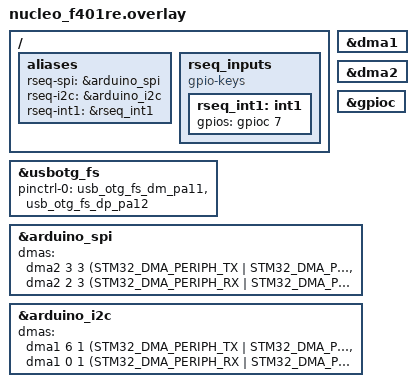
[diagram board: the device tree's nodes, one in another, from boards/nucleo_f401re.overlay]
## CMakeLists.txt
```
# SPDX-License-Identifier: Apache-2.0
#
# rseq MCU firmware (C + Rust). rust_cargo_application() builds the rustapp
# staticlib and provides main()→rust_main(); the C files are the FFI shims.

cmake_minimum_required(VERSION 3.20.0)

find_package(Zephyr REQUIRED HINTS $ENV{ZEPHYR_BASE})

project(rseq_f429zi)

rust_cargo_application()

target_sources(app PRIVATE
  src/zephyr_cdc_ffi.c
  src/zephyr_bus_ffi.c
)
```

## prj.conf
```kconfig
# SPDX-License-Identifier: Apache-2.0
#
# rseq MCU firmware (Nucleo boards): rseq-link over USB CDC + physical buses.

# ---- Rust (zephyr crate supplies global allocator + panic handler + log) ----
CONFIG_RUST=y
CONFIG_RUST_ALLOC=y

# ---- Console / logs on USART3 (ST-Link VCP) ----
CONFIG_CONSOLE=y
CONFIG_UART_CONSOLE=y
CONFIG_PRINTK=y
CONFIG_LOG=y
CONFIG_LOG_BACKEND_UART=y
CONFIG_LOG_BACKEND_RTT=n
CONFIG_USE_SEGGER_RTT=n
CONFIG_SERIAL=y
CONFIG_UART_INTERRUPT_DRIVEN=y

# ---- New USB CDC device stack (1 CDC port = rseq-link transport) ----
CONFIG_USB_DEVICE_STACK_NEXT=y
CONFIG_USBD_CDC_ACM_CLASS=y
CONFIG_CDC_ACM_SERIAL_INITIALIZE_AT_BOOT=n
CONFIG_UART_LINE_CTRL=y
CONFIG_HWINFO=y

# ---- Physical buses exposed to the rseq VM ----
CONFIG_SPI=y
CONFIG_I2C=y
CONFIG_GPIO=y

# ---- Stack: rseq-vm raw buffer + scratch + TracingBus frame during EXEC/IRQ ----
CONFIG_MAIN_STACK_SIZE=24576

# Avoid UART conflicts; console stays on USART3, protocol on USB CDC.
CONFIG_SHELL=n
```

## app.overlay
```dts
/*
 * Copyright (c) 2026 rseq contributors
 * SPDX-License-Identifier: Apache-2.0
 *
 * rseq MCU common overlay.
 *
 * Board-specific wiring lives in boards/<board>.overlay. Chip bus/address
 * selection is supplied by the rseq script, so this file stays transport-only.
 */

/* USB CDC-ACM — the rseq-link transport channel. */
&zephyr_udc0 {
	cdc_acm_uart0: cdc_acm_uart0 {
		compatible = "zephyr,cdc-acm-uart";
	};
};
```

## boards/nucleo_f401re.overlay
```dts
/*
 * Copyright (c) 2026 rseq contributors
 * SPDX-License-Identifier: Apache-2.0
 *
 * Nucleo F401RE board wiring for the rseq generic bus bridge firmware.
 *
 * Note: the application still needs a zephyr_udc0 USB device node for the CDC
 * transport. This board overlay exposes the Arduino bus/INT wiring;
 * USB availability is determined by the upstream board/SoC devicetree.
 */

#include <zephyr/dt-bindings/gpio/gpio.h>

zephyr_udc0: &usbotg_fs {
	pinctrl-0 = <&usb_otg_fs_dm_pa11 &usb_otg_fs_dp_pa12>;
	pinctrl-names = "default";
	status = "okay";
};

#include "../app.overlay"

/ {
	aliases {
		rseq-spi = &arduino_spi;
		rseq-i2c = &arduino_i2c;
		rseq-int1 = &rseq_int1;
	};

	rseq_inputs {
		compatible = "gpio-keys";

		/* Arduino D9 on Nucleo F401RE. */
		rseq_int1: int1 {
			gpios = <&gpioc 7 GPIO_ACTIVE_HIGH>;
		};
	};
};

&dma1 {
	status = "okay";
};

&dma2 {
	status = "okay";
};

&gpioc {
	status = "okay";
};

&arduino_spi {
	dmas = <&dma2 3 3 (STM32_DMA_PERIPH_TX | STM32_DMA_PRIORITY_HIGH)
		STM32_DMA_FIFO_FULL>,
	       <&dma2 2 3 (STM32_DMA_PERIPH_RX | STM32_DMA_PRIORITY_HIGH)
		STM32_DMA_FIFO_FULL>;
	dma-names = "tx", "rx";
};

&arduino_i2c {
	dmas = <&dma1 6 1 (STM32_DMA_PERIPH_TX | STM32_DMA_PRIORITY_HIGH)
		STM32_DMA_FIFO_FULL>,
	       <&dma1 0 1 (STM32_DMA_PERIPH_RX | STM32_DMA_PRIORITY_HIGH)
		STM32_DMA_FIFO_FULL>;
	dma-names = "tx", "rx";
};
```

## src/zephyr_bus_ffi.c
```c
#include <stddef.h>
#include <stdint.h>
#include <stdbool.h>
#include <errno.h>

#include <zephyr/device.h>
#include <zephyr/drivers/gpio.h>
#include <zephyr/drivers/i2c.h>
#include <zephyr/drivers/spi.h>
#include <zephyr/kernel.h>
#include <zephyr/sys/printk.h>

#define RSEQ_SPI_BUS_NODE   DT_ALIAS(rseq_spi)
#define RSEQ_I2C_BUS_NODE   DT_ALIAS(rseq_i2c)
#define RSEQ_INT1_NODE      DT_ALIAS(rseq_int1)

#define RSEQ_HAS_SPI                                                           \
    (DT_NODE_EXISTS(RSEQ_SPI_BUS_NODE) &&                                      \
     DT_NODE_HAS_PROP(RSEQ_SPI_BUS_NODE, cs_gpios))
#define RSEQ_HAS_I2C DT_NODE_EXISTS(RSEQ_I2C_BUS_NODE)
#define RSEQ_HAS_INT1 DT_NODE_EXISTS(RSEQ_INT1_NODE)

#define SPI_BUS_FREQUENCY 8000000U
#define SPI_BUS_SLAVE     0U

#define SPI_BUS_OPERATION                                                      \
    (SPI_OP_MODE_MASTER | SPI_WORD_SET(8) | SPI_TRANSFER_MSB)

#if RSEQ_HAS_SPI
static const struct device *const spi_bus = DEVICE_DT_GET(RSEQ_SPI_BUS_NODE);
static const struct spi_config    spi_cfg = {
       .frequency = SPI_BUS_FREQUENCY,
       .operation = SPI_BUS_OPERATION,
       .slave     = SPI_BUS_SLAVE,
};
static const struct gpio_dt_spec spi_cs =
    GPIO_DT_SPEC_GET_BY_IDX(RSEQ_SPI_BUS_NODE, cs_gpios, 0);
#endif

#if RSEQ_HAS_I2C
static const struct device *const i2c_bus = DEVICE_DT_GET(RSEQ_I2C_BUS_NODE);
#endif

#if RSEQ_HAS_INT1
static const struct gpio_dt_spec rseq_int1 =
    GPIO_DT_SPEC_GET(RSEQ_INT1_NODE, gpios);
static struct gpio_callback rseq_int1_cb;
K_SEM_DEFINE(rseq_int1_sem, 0, 1);
static bool rseq_int1_ready;
#endif

// 声明 Rust 侧的回调函数
extern void rust_irq_int1_triggered(void);
extern void rust_event_notify(void);

#if RSEQ_HAS_INT1
static void rseq_int1_isr(const struct device *port, struct gpio_callback *cb,
                          uint32_t pins)
{
    (void)port;
    (void)cb;
    (void)pins;
    k_sem_give(&rseq_int1_sem);
    // 同时通知 Rust 侧设置待处理标志
    rust_irq_int1_triggered();
    rust_event_notify();
}

static void rseq_int1_sem_drain(void)
{
    while (k_sem_take(&rseq_int1_sem, K_NO_WAIT) == 0) {
    }
}
#endif

int rust_spi_bus_is_ready(void)
{
#if RSEQ_HAS_SPI
    return device_is_ready(spi_bus) ? 0 : -ENODEV;
#else
    return -ENOTSUP;
#endif
}

int rust_spi_bus_transceive(const uint8_t *tx, size_t tx_len, uint8_t *rx,
                            size_t rx_len)
{
#if RSEQ_HAS_SPI
    const struct spi_buf tx_buf = {
        .buf = (void *)tx,
        .len = tx_len,
    };
    const struct spi_buf_set tx_set = {
        .buffers = &tx_buf,
        .count   = tx != NULL ? 1 : 0,
    };
    struct spi_buf rx_buf = {
        .buf = rx,
        .len = rx_len,
    };
    const struct spi_buf_set rx_set = {
        .buffers = &rx_buf,
        .count   = rx != NULL ? 1 : 0,
    };

    if (!device_is_ready(spi_bus)) {
        return -ENODEV;
    }

    return spi_transceive(spi_bus, &spi_cfg, tx != NULL ? &tx_set : NULL,
                          rx != NULL ? &rx_set : NULL);
#else
    (void)tx;
    (void)tx_len;
    (void)rx;
    (void)rx_len;
    return -ENOTSUP;
#endif
}

int rust_spi_cs_init(void)
{
#if RSEQ_HAS_SPI
    if (!gpio_is_ready_dt(&spi_cs)) {
        return -ENODEV;
    }

    return gpio_pin_configure_dt(&spi_cs, GPIO_OUTPUT_INACTIVE);
#else
    return -ENOTSUP;
#endif
}

int rust_spi_cs_set_low(void)
{
#if RSEQ_HAS_SPI
    return gpio_pin_set_raw(spi_cs.port, spi_cs.pin, 0);
#else
    return -ENOTSUP;
#endif
}

int rust_spi_cs_set_high(void)
{
#if RSEQ_HAS_SPI
    return gpio_pin_set_raw(spi_cs.port, spi_cs.pin, 1);
#else
    return -ENOTSUP;
#endif
}

int rust_i2c_bus_is_ready(void)
{
#if RSEQ_HAS_I2C
    return device_is_ready(i2c_bus) ? 0 : -ENODEV;
#else
    return -ENOTSUP;
#endif
}

int rust_i2c_bus_read(uint16_t addr, uint8_t *data, size_t len)
{
#if RSEQ_HAS_I2C
    if (!device_is_ready(i2c_bus)) {
        return -ENODEV;
    }

    return i2c_read(i2c_bus, data, len, addr);
#else
    (void)addr;
    (void)data;
    (void)len;
    return -ENOTSUP;
#endif
}

int rust_i2c_bus_write(uint16_t addr, const uint8_t *data, size_t len)
{
#if RSEQ_HAS_I2C
    if (!device_is_ready(i2c_bus)) {
        return -ENODEV;
    }

    return i2c_write(i2c_bus, data, len, addr);
#else
    (void)addr;
    (void)data;
    (void)len;
    return -ENOTSUP;
#endif
}

int rust_i2c_bus_write_read(uint16_t addr, const uint8_t *write_data,
                            size_t write_len, uint8_t *read_data,
                            size_t read_len)
{
#if RSEQ_HAS_I2C
    if (!device_is_ready(i2c_bus)) {
        return -ENODEV;
    }

    return i2c_write_read(i2c_bus, addr, write_data, write_len, read_data,
                          read_len);
#else
    (void)addr;
    (void)write_data;
    (void)write_len;
    (void)read_data;
    (void)read_len;
    return -ENOTSUP;
#endif
}

int rust_i3c_bus_is_ready(void)
{
    return -ENOTSUP;
}

int rust_i3c_bus_write_read(uint16_t addr, const uint8_t *write_data,
                            size_t write_len, uint8_t *read_data,
                            size_t read_len)
{
    (void)addr;
    (void)write_data;
    (void)write_len;
    (void)read_data;
    (void)read_len;
    return -ENOTSUP;
}

int rust_i3c_bus_write(uint16_t addr, const uint8_t *data, size_t len)
{
    (void)addr;
    (void)data;
    (void)len;
    return -ENOTSUP;
}

int rust_irq_init(void)
{
#if RSEQ_HAS_INT1
    int ret;

    if (rseq_int1_ready) {
        return 0;
    }

    if (!gpio_is_ready_dt(&rseq_int1)) {
        return -ENODEV;
    }

    ret = gpio_pin_configure_dt(&rseq_int1, GPIO_INPUT);
    if (ret != 0) {
        return ret;
    }

    gpio_init_callback(&rseq_int1_cb, rseq_int1_isr, BIT(rseq_int1.pin));
    ret = gpio_add_callback(rseq_int1.port, &rseq_int1_cb);
    if (ret != 0) {
        return ret;
    }

    ret = gpio_pin_interrupt_configure_dt(&rseq_int1, GPIO_INT_EDGE_TO_ACTIVE);
    if (ret != 0) {
        (void)gpio_remove_callback(rseq_int1.port, &rseq_int1_cb);
        return ret;
    }

    rseq_int1_sem_drain();
    rseq_int1_ready = true;
    return 0;
#else
    return -ENOTSUP;
#endif
}

int rust_irq_wait(uint8_t pin, uint32_t timeout_ms)
{
#if RSEQ_HAS_INT1
    int ret;
    int level;
    int level_after;

    if (pin != 0U) {
        return -2;
    }

    ret = rust_irq_init();
    if (ret != 0) {
        return -3;
    }

    rseq_int1_sem_drain();
    level = gpio_pin_get_dt(&rseq_int1);
    if (level < 0) {
        return -3;
    }

    printk("rseq: irq wait pin=%u timeout=%u entry_level=%d\n",
           (unsigned int)pin, (unsigned int)timeout_ms, level);
    if (level > 0) {
        printk("rseq: irq wait pin=%u already high, waiting next edge\n",
               (unsigned int)pin);
    }

    ret = k_sem_take(&rseq_int1_sem, K_MSEC(timeout_ms));
    if (ret == 0) {
        level_after = gpio_pin_get_dt(&rseq_int1);
        printk("rseq: irq edge pin=%u level=%d\n", (unsigned int)pin,
               level_after);
        return 0;
    }

    printk("rseq: irq wait timeout pin=%u\n", (unsigned int)pin);
    return -1;
#else
    (void)pin;
    (void)timeout_ms;
    return -ENOTSUP;
#endif
}
```

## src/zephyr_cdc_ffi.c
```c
/*
 * rseq MCU — USB CDC + UART FFI for Rust.
 *
 *  - rust_usb_enable(): bring up Zephyr's "new" USB device stack (one CDC-ACM
 *    port) so the host sees "rseq MCU CDC". Each step is printk'd for
 *    bring-up diagnostics (logs go to USART3 / ST-Link VCP).
 *  - rust_uart_init/read/write: the CDC-ACM UART (RX irq→K_MSGQ, blocking;
 *    TX uart_poll_out under a mutex) used as the rseq-link Transport.
 *  - rust_uptime_us/kernel_delay_us/sleep_ms: timing for report metadata and
 *    the Bus::delay_us path.
 *  - rust_printk: raw console output from Rust (bypasses the log backend).
 *
 * SPDX-License-Identifier: Apache-2.0
 */

#include <stddef.h>
#include <stdint.h>
#include <errno.h>

#include <zephyr/kernel.h>
#include <zephyr/device.h>
#include <zephyr/drivers/uart.h>
#include <zephyr/sys/printk.h>

#include <zephyr/usb/usbd.h>
#include <zephyr/usb/usb_ch9.h>

/* ---- USB device context + descriptors (self-contained, 1 CDC port) ---- */

#define USB_VID 0x0483
#define USB_PID 0x5740 /* ST + generic STM32 CDC; host binds cdc_acm/usbser */

USBD_DEVICE_DEFINE(udev,
		   DEVICE_DT_GET(DT_NODELABEL(zephyr_udc0)),
		   USB_VID, USB_PID);

USBD_DESC_LANG_DEFINE(udev_lang);
USBD_DESC_MANUFACTURER_DEFINE(udev_mfr, "rseq");
USBD_DESC_PRODUCT_DEFINE(udev_product, "rseq MCU CDC");
USBD_DESC_SERIAL_NUMBER_DEFINE(udev_sn); /* from hwinfo (chip UID) */
USBD_DESC_CONFIG_DEFINE(udev_cfg_desc, "CDC");

USBD_CONFIGURATION_DEFINE(udev_config,
			  USB_SCD_SELF_POWERED,
			  0, &udev_cfg_desc);

static void udev_msg_cb(struct usbd_context *const ctx, const struct usbd_msg *msg)
{
	if (usbd_can_detect_vbus(ctx)) {
		if (msg->type == USBD_MSG_VBUS_READY) {
			(void)usbd_enable(ctx);
		} else if (msg->type == USBD_MSG_VBUS_REMOVED) {
			(void)usbd_disable(ctx);
		}
	}
}

int rust_usb_enable(void)
{
	int err;

	err  = usbd_add_descriptor(&udev, &udev_lang);
	err |= usbd_add_descriptor(&udev, &udev_mfr);
	err |= usbd_add_descriptor(&udev, &udev_product);
	err |= usbd_add_descriptor(&udev, &udev_sn);
	if (err) {
		printk("rseq: usbd_add_descriptor=%d\n", err);
		return -EIO;
	}

	err = usbd_add_configuration(&udev, USBD_SPEED_FS, &udev_config);
	if (err) {
		printk("rseq: usbd_add_configuration=%d\n", err);
		return err;
	}

	/* Registers the cdc_acm_uart0 instance as a class function. */
	err = usbd_register_all_classes(&udev, USBD_SPEED_FS, 1, NULL);
	if (err) {
		printk("rseq: usbd_register_all_classes=%d\n", err);
		return err;
	}

	(void)usbd_device_set_code_triple(&udev, USBD_SPEED_FS,
					  USB_BCC_MISCELLANEOUS, 0x02, 0x01);

	err = usbd_msg_register_cb(&udev, udev_msg_cb);
	if (err) {
		printk("rseq: usbd_msg_register_cb=%d\n", err);
		return err;
	}

	err = usbd_init(&udev);
	if (err) {
		printk("rseq: usbd_init=%d\n", err);
		return err;
	}

	if (!usbd_can_detect_vbus(&udev)) {
		err = usbd_enable(&udev);
		if (err) {
			printk("rseq: usbd_enable=%d\n", err);
			return err;
		}
	}

	printk("rseq: usb ok\n");
	return 0;
}

/* ---- CDC-ACM UART (cdc_acm_uart0 from app.overlay) ---- */

#if DT_NODE_EXISTS(DT_NODELABEL(cdc_acm_uart0))
static const struct device *const serial_dev = DEVICE_DT_GET(DT_NODELABEL(cdc_acm_uart0));
#else
#error "cdc_acm_uart0 not found in devicetree (check app.overlay)"
#endif

K_MSGQ_DEFINE(uart_rx_msgq, sizeof(uint8_t), 1024, 4);
K_MUTEX_DEFINE(uart_tx_mutex);
K_SEM_DEFINE(rseq_event_sem, 0, 1);

void rust_event_notify(void)
{
	k_sem_give(&rseq_event_sem);
}

int rust_event_wait(uint32_t timeout_ms)
{
	return k_sem_take(&rseq_event_sem,
			  timeout_ms == 0U ? K_FOREVER : K_MSEC(timeout_ms));
}

static void uart_irq_cb(const struct device *dev, void *user_data)
{
	ARG_UNUSED(user_data);

	uart_irq_update(dev);
	if (!uart_irq_rx_ready(dev)) {
		return;
	}

	uint8_t buf[32];

	while (1) {
		int n = uart_fifo_read(dev, buf, sizeof(buf));
		if (n <= 0) {
			break;
		}

		for (int i = 0; i < n; i++) {
			(void)k_msgq_put(&uart_rx_msgq, &buf[i], K_NO_WAIT);
		}
		rust_event_notify();
	}
}

int rust_uart_init(void)
{
	if (!device_is_ready(serial_dev)) {
		printk("rseq: cdc_acm_uart0 not ready\n");
		return -ENODEV;
	}

	k_msgq_purge(&uart_rx_msgq);

	int ret = uart_irq_callback_user_data_set(serial_dev, uart_irq_cb, NULL);
	if (ret) {
		printk("rseq: uart_irq_callback_set=%d\n", ret);
		return ret;
	}

	uart_irq_rx_enable(serial_dev);
	return 0;
}

/* Non-blocking read: always returns immediately (0 if no data).
 * Used for IRQ polling mode. */
int rust_uart_read(uint8_t *buf, size_t len)
{
	if (len == 0 || buf == NULL) {
		return -EINVAL;
	}

	/* Non-blocking: return immediately if no data */
	int ret = k_msgq_get(&uart_rx_msgq, &buf[0], K_NO_WAIT);
	if (ret) {
		/* No data available, return 0 (not an error) */
		return 0;
	}

	size_t count = 1;
	while (count < len) {
		if (k_msgq_get(&uart_rx_msgq, &buf[count], K_NO_WAIT) != 0) {
			break;
		}
		count++;
	}

	return (int)count;
}

int rust_uart_write(const uint8_t *data, size_t len)
{
	if (len != 0 && data == NULL) {
		return -EINVAL;
	}

	if (!device_is_ready(serial_dev)) {
		return -ENODEV;
	}

	k_mutex_lock(&uart_tx_mutex, K_FOREVER);
	for (size_t i = 0; i < len; i++) {
		uart_poll_out(serial_dev, data[i]);
	}
	k_mutex_unlock(&uart_tx_mutex);
	return 0;
}

void rust_kernel_sleep_ms(uint32_t ms)
{
	k_sleep(K_MSEC(ms));
}

uint64_t rust_uptime_us(void)
{
	return k_cyc_to_us_floor64(k_cycle_get_64());
}

void rust_kernel_delay_us(uint32_t us)
{
	if (us == 0) {
		return;
	}

	uint32_t ms = us / 1000U;
	uint32_t rem = us % 1000U;

	if (ms != 0U) {
		k_sleep(K_MSEC(ms));
	}

	if (rem != 0U) {
		k_busy_wait(rem);
	}
}

/* Raw console output for Rust (bypasses the log backend; goes to USART3). */
void rust_printk(const char *s, size_t len)
{
	printk("%.*s", (int)len, s);
}
```
